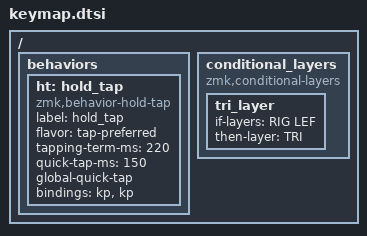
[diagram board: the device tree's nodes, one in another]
// SPDX-License-Identifier: MIT

#include <behaviors.dtsi>
#include <dt-bindings/zmk/keys.h>
#include <dt-bindings/zmk/bt.h>
#include <dt-bindings/zmk/outputs.h>

// Home row mods macro
#define HRML(k2,k3,k4) &ht LALT k2  &ht LCTRL k3  &ht LGUI k4
#define HRMR(k1,k2,k3) &ht RGUI k1  &ht RCTRL k2  &ht RALT k3
#define WHRML(k2,k3,k4) &ht LALT k2  &ht LGUI k3  &ht LCTRL k4
#define WHRMR(k1,k2,k3) &ht RCTRL k1  &ht RGUI k2  &ht RALT k3

#define MAC 0
#define WIN 1
#define RIG 2
#define LEF 3
#define TRI 4

/ {
    behaviors {
        ht: hold_tap {
            label = "hold_tap";
            compatible = "zmk,behavior-hold-tap";
            #binding-cells = <2>;
            flavor = "tap-preferred";
            tapping-term-ms = <220>;
            quick-tap-ms = <150>;
            global-quick-tap;
            bindings = <&kp>, <&kp>;
        };
    };

    conditional_layers {
        compatible = "zmk,conditional-layers";
        tri_layer {
            if-layers = <RIG LEF>;
            then-layer = <TRI>;
        };
    };
};
